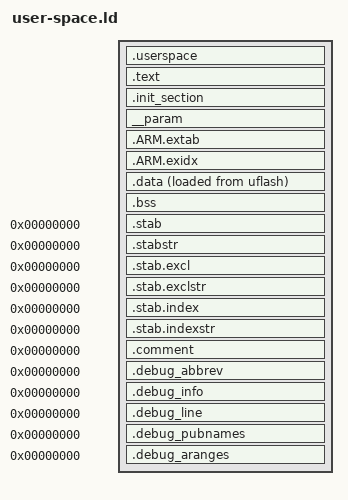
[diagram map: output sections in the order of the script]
/****************************************************************************
 * boards/arm/stm32f7/stm32f746g-disco/scripts/user-space.ld
 *
 *   Copyright (C) 2015 Gregory Nutt. All rights reserved.
 *   Author: Gregory Nutt <gnutt@nuttx.org>
 *
 * Redistribution and use in source and binary forms, with or without
 * modification, are permitted provided that the following conditions
 * are met:
 *
 * 1. Redistributions of source code must retain the above copyright
 *    notice, this list of conditions and the following disclaimer.
 * 2. Redistributions in binary form must reproduce the above copyright
 *    notice, this list of conditions and the following disclaimer in
 *    the documentation and/or other materials provided with the
 *    distribution.
 * 3. Neither the name NuttX nor the names of its contributors may be
 *    used to endorse or promote products derived from this software
 *    without specific prior written permission.
 *
 * THIS SOFTWARE IS PROVIDED BY THE COPYRIGHT HOLDERS AND CONTRIBUTORS
 * "AS IS" AND ANY EXPRESS OR IMPLIED WARRANTIES, INCLUDING, BUT NOT
 * LIMITED TO, THE IMPLIED WARRANTIES OF MERCHANTABILITY AND FITNESS
 * FOR A PARTICULAR PURPOSE ARE DISCLAIMED. IN NO EVENT SHALL THE
 * COPYRIGHT OWNER OR CONTRIBUTORS BE LIABLE FOR ANY DIRECT, INDIRECT,
 * INCIDENTAL, SPECIAL, EXEMPLARY, OR CONSEQUENTIAL DAMAGES (INCLUDING,
 * BUT NOT LIMITED TO, PROCUREMENT OF SUBSTITUTE GOODS OR SERVICES; LOSS
 * OF USE, DATA, OR PROFITS; OR BUSINESS INTERRUPTION) HOWEVER CAUSED
 * AND ON ANY THEORY OF LIABILITY, WHETHER IN CONTRACT, STRICT
 * LIABILITY, OR TORT (INCLUDING NEGLIGENCE OR OTHERWISE) ARISING IN
 * ANY WAY OUT OF THE USE OF THIS SOFTWARE, EVEN IF ADVISED OF THE
 * POSSIBILITY OF SUCH DAMAGE.
 *
 ****************************************************************************/

/* NOTE:  This depends on the memory.ld script having been included prior to
 * this script.
 */
EXTERN(userspace)
OUTPUT_ARCH(arm)
SECTIONS
{
    .userspace : {
        *(.userspace)
    } > uflash

    .text : {
        _stext = ABSOLUTE(.);
        *(.text .text.*)
        *(.fixup)
        *(.gnu.warning)
        *(.rodata .rodata.*)
        *(.gnu.linkonce.t.*)
        *(.glue_7)
        *(.glue_7t)
        *(.got)
        *(.gcc_except_table)
        *(.gnu.linkonce.r.*)
        _etext = ABSOLUTE(.);
    } > uflash

    .init_section : {
        _sinit = ABSOLUTE(.);
        KEEP(*(.init_array .init_array.*))
        _einit = ABSOLUTE(.);
    } > uflash

    /*
     * Construction data for parameters.
     */
     __param ALIGN(4): {
     __param_start = ABSOLUTE(.);
     KEEP(*(__param*))
     __param_end = ABSOLUTE(.);
     } > uflash

    .ARM.extab : {
        *(.ARM.extab*)
    } > uflash

    __exidx_start = ABSOLUTE(.);
    .ARM.exidx : {
        *(.ARM.exidx*)
    } > uflash

    __exidx_end = ABSOLUTE(.);

    _eronly = ABSOLUTE(.);

    .data : {
        _sdata = ABSOLUTE(.);
        *(.data .data.*)
        *(.gnu.linkonce.d.*)
        CONSTRUCTORS
        . = ALIGN(4);
        _edata = ABSOLUTE(.);
    } > usram AT > uflash

    .bss : {
        _sbss = ABSOLUTE(.);
        *(.bss .bss.*)
        *(.gnu.linkonce.b.*)
        *(COMMON)
        /* Kernel heap start at _ebss, make _ebss MPU-friendly aligned */
        . = ALIGN(0x1000);
        _ebss = ABSOLUTE(.);
    } > usram

    /* Stabs debugging sections */

    .stab 0 : { *(.stab) }
    .stabstr 0 : { *(.stabstr) }
    .stab.excl 0 : { *(.stab.excl) }
    .stab.exclstr 0 : { *(.stab.exclstr) }
    .stab.index 0 : { *(.stab.index) }
    .stab.indexstr 0 : { *(.stab.indexstr) }
    .comment 0 : { *(.comment) }
    .debug_abbrev 0 : { *(.debug_abbrev) }
    .debug_info 0 : { *(.debug_info) }
    .debug_line 0 : { *(.debug_line) }
    .debug_pubnames 0 : { *(.debug_pubnames) }
    .debug_aranges 0 : { *(.debug_aranges) }
}
